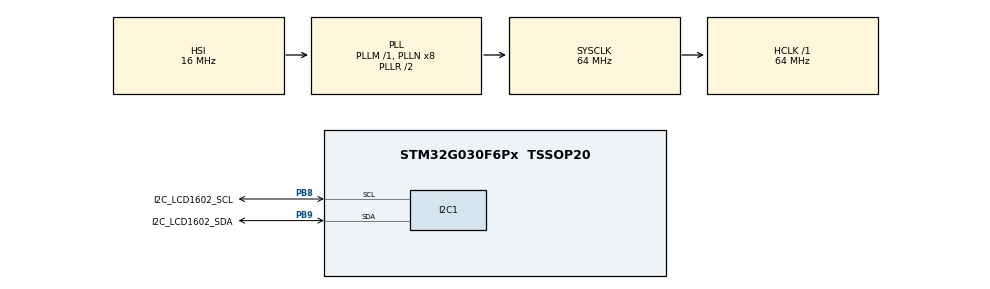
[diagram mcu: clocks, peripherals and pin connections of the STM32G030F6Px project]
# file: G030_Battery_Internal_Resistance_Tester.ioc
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ADC1.Channel-0\#ChannelRegularConversion=ADC_CHANNEL_VREFINT
ADC1.NbrOfConversionFlag=1
ADC1.Rank-0\#ChannelRegularConversion=1
ADC1.SamplingTime-0\#ChannelRegularConversion=ADC_SAMPLINGTIME_COMMON_1
ADC1.SelectedChannel=ADC_CHANNEL_VREFINT
ADC1.master=1
I2C1.Timing=0x10B17DB5
Mcu.Family=STM32G0
Mcu.Name=STM32G030F6Px
Mcu.Package=TSSOP20
PA13.Mode=Serial_Wire
PA13.Signal=SYS_SWDIO
PA14-BOOT0.Mode=Serial_Wire
PA14-BOOT0.Signal=SYS_SWCLK
PA14-BOOT0__PA15.StandardMode=true
PB0__PB1__PB2__PA8.StandardMode=true
PB3__PB4__PB5__PB6.StandardMode=true
PB7__PB8.StandardMode=true
PB8.GPIO_Label=I2C_LCD1602_SCL
PB8.Mode=I2C
PB8.Signal=I2C1_SCL
PB9.GPIO_Label=I2C_LCD1602_SDA
PB9.Mode=I2C
PB9.Signal=I2C1_SDA
PC14-OSC32_IN\ (PC14)__PB9.StandardMode=true
ProjectManager.HeapSize=0x200
ProjectManager.StackSize=0x400
ProjectManager.TargetToolchain=STM32CubeIDE
RCC.ADCFreq_Value=64000000
RCC.AHBFreq_Value=64000000
RCC.CortexFreq_Value=64000000
RCC.EXTERNAL_CLOCK_VALUE=12288000
RCC.HCLKFreq_Value=64000000
RCC.HSE_VALUE=8000000
RCC.HSI_VALUE=16000000
RCC.LSE_VALUE=32768
RCC.SYSCLKFreq_VALUE=64000000
RCC.SYSCLKSource=RCC_SYSCLKSOURCE_PLLCLK
RCC.VCOOutputFreq_Value=128000000
VP_ADC1_Vref_Input.Mode=IN-Vrefint
board=custom

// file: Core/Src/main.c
/* USER CODE BEGIN Header */
/**
  ******************************************************************************
  * @file           : main.c
  * @brief          : Main program body
  ******************************************************************************
  * @attention
  *
  * Copyright (c) 2026 STMicroelectronics.
  * All rights reserved.
  *
  * This software is licensed under terms that can be found in the LICENSE file
  * in the root directory of this software component.
  * If no LICENSE file comes with this software, it is provided AS-IS.
  *
  ******************************************************************************
  */
/* USER CODE END Header */
#include "main.h"

ADC_HandleTypeDef hadc1;

I2C_HandleTypeDef hi2c1;

void SystemClock_Config(void);
static void MX_GPIO_Init(void);
static void MX_ADC1_Init(void);
static void MX_I2C1_Init(void);

/* USER CODE BEGIN 0 */
#define LCD_RS 0x01U
#define LCD_EN 0x04U
#define LCD_BL 0x08U
static uint16_t lcd_address;

static void LCD_Raw(uint8_t b)
{
  (void)HAL_I2C_Master_Transmit(&hi2c1, lcd_address, &b, 1, 100);
}
static void LCD_Nibble(uint8_t n, uint8_t rs)
{
  uint8_t b = (uint8_t)((n & 0xF0U) | LCD_BL | rs);
  LCD_Raw((uint8_t)(b | LCD_EN));
  HAL_Delay(1);
  LCD_Raw(b);
  HAL_Delay(1);
}
static void LCD_Send(uint8_t b, uint8_t rs)
{
  LCD_Nibble(b, rs);
  LCD_Nibble((uint8_t)(b << 4), rs);
}
static void LCD_Cmd(uint8_t c)
{
  LCD_Send(c, 0);
  if (c == 0x01U || c == 0x02U) HAL_Delay(2);
}
static void LCD_Print(const char *p)
{
  while (*p) LCD_Send((uint8_t)*p++, LCD_RS);
}
static uint8_t LCD_Detect(void)
{
  /* Common PCF8574/PCF8574A backpack address range. */
  for (uint8_t a = 0x20U; a <= 0x3FU; a++)
  {
    if (HAL_I2C_IsDeviceReady(&hi2c1, (uint16_t)(a << 1), 2, 20) == HAL_OK)
    {
      lcd_address = (uint16_t)(a << 1);
      return 1;
    }
  }
  return 0;
}
static void LCD_Init(void)
{
  HAL_Delay(50);
  LCD_Raw(LCD_BL);
  HAL_Delay(50);
  LCD_Nibble(0x30, 0);
  HAL_Delay(5);
  LCD_Nibble(0x30, 0);
  HAL_Delay(2);
  LCD_Nibble(0x30, 0);
  LCD_Nibble(0x20, 0);
  LCD_Cmd(0x28);
  LCD_Cmd(0x08);
  LCD_Cmd(0x01);
  LCD_Cmd(0x06);
  LCD_Cmd(0x0C);
}

/* USER CODE END 0 */

int main(void)
{

  /* MCU Configuration--------------------------------------------------------*/

  /* Reset of all peripherals, Initializes the Flash interface and the Systick. */
  HAL_Init();

  /* Configure the system clock */
  SystemClock_Config();

  /* Initialize all configured peripherals */
  MX_GPIO_Init();
  MX_ADC1_Init();
  MX_I2C1_Init();
  /* USER CODE BEGIN 2 */
  if (LCD_Detect())
  {
    LCD_Init();
    LCD_Cmd(0x80);
    LCD_Print("STM32G030 READY");
    LCD_Cmd(0xC0);
    LCD_Print("LCD1602 I2C OK!");
  }

  /* USER CODE END 2 */

  /* Infinite loop */
  while (1)
  {

  }
}

void SystemClock_Config(void)
{
  RCC_OscInitTypeDef RCC_OscInitStruct = {0};
  RCC_ClkInitTypeDef RCC_ClkInitStruct = {0};

  /** Configure the main internal regulator output voltage
  */
  HAL_PWREx_ControlVoltageScaling(PWR_REGULATOR_VOLTAGE_SCALE1);

  /** Initializes the RCC Oscillators according to the specified parameters
  * in the RCC_OscInitTypeDef structure.
  */
  RCC_OscInitStruct.OscillatorType = RCC_OSCILLATORTYPE_HSI;
  RCC_OscInitStruct.HSIState = RCC_HSI_ON;
  RCC_OscInitStruct.HSIDiv = RCC_HSI_DIV1;
  RCC_OscInitStruct.HSICalibrationValue = RCC_HSICALIBRATION_DEFAULT;
  RCC_OscInitStruct.PLL.PLLState = RCC_PLL_ON;
  RCC_OscInitStruct.PLL.PLLSource = RCC_PLLSOURCE_HSI;
  RCC_OscInitStruct.PLL.PLLM = RCC_PLLM_DIV1;
  RCC_OscInitStruct.PLL.PLLN = 8;
  RCC_OscInitStruct.PLL.PLLP = RCC_PLLP_DIV2;
  RCC_OscInitStruct.PLL.PLLR = RCC_PLLR_DIV2;
  if (HAL_RCC_OscConfig(&RCC_OscInitStruct) != HAL_OK)
  {
    Error_Handler();
  }

  /** Initializes the CPU, AHB and APB buses clocks
  */
  RCC_ClkInitStruct.ClockType = RCC_CLOCKTYPE_HCLK|RCC_CLOCKTYPE_SYSCLK
                              |RCC_CLOCKTYPE_PCLK1;
  RCC_ClkInitStruct.SYSCLKSource = RCC_SYSCLKSOURCE_PLLCLK;
  RCC_ClkInitStruct.AHBCLKDivider = RCC_SYSCLK_DIV1;
  RCC_ClkInitStruct.APB1CLKDivider = RCC_HCLK_DIV1;

  if (HAL_RCC_ClockConfig(&RCC_ClkInitStruct, FLASH_LATENCY_2) != HAL_OK)
  {
    Error_Handler();
  }
}

static void MX_ADC1_Init(void)
{

  ADC_ChannelConfTypeDef sConfig = {0};

  /** Configure the global features of the ADC (Clock, Resolution, Data Alignment and number of conversion)
  */
  hadc1.Instance = ADC1;
  hadc1.Init.ClockPrescaler = ADC_CLOCK_SYNC_PCLK_DIV2;
  hadc1.Init.Resolution = ADC_RESOLUTION_12B;
  hadc1.Init.DataAlign = ADC_DATAALIGN_RIGHT;
  hadc1.Init.ScanConvMode = ADC_SCAN_DISABLE;
  hadc1.Init.EOCSelection = ADC_EOC_SINGLE_CONV;
  hadc1.Init.LowPowerAutoWait = DISABLE;
  hadc1.Init.LowPowerAutoPowerOff = DISABLE;
  hadc1.Init.ContinuousConvMode = DISABLE;
  hadc1.Init.NbrOfConversion = 1;
  hadc1.Init.DiscontinuousConvMode = DISABLE;
  hadc1.Init.ExternalTrigConv = ADC_SOFTWARE_START;
  hadc1.Init.ExternalTrigConvEdge = ADC_EXTERNALTRIGCONVEDGE_NONE;
  hadc1.Init.DMAContinuousRequests = DISABLE;
  hadc1.Init.Overrun = ADC_OVR_DATA_PRESERVED;
  hadc1.Init.SamplingTimeCommon1 = ADC_SAMPLETIME_1CYCLE_5;
  hadc1.Init.SamplingTimeCommon2 = ADC_SAMPLETIME_1CYCLE_5;
  hadc1.Init.OversamplingMode = DISABLE;
  hadc1.Init.TriggerFrequencyMode = ADC_TRIGGER_FREQ_HIGH;
  if (HAL_ADC_Init(&hadc1) != HAL_OK)
  {
    Error_Handler();
  }

  /** Configure Regular Channel
  */
  sConfig.Channel = ADC_CHANNEL_VREFINT;
  sConfig.Rank = ADC_REGULAR_RANK_1;
  sConfig.SamplingTime = ADC_SAMPLINGTIME_COMMON_1;
  if (HAL_ADC_ConfigChannel(&hadc1, &sConfig) != HAL_OK)
  {
    Error_Handler();
  }

}

static void MX_I2C1_Init(void)
{

  hi2c1.Instance = I2C1;
  hi2c1.Init.Timing = 0x10B17DB5;
  hi2c1.Init.OwnAddress1 = 0;
  hi2c1.Init.AddressingMode = I2C_ADDRESSINGMODE_7BIT;
  hi2c1.Init.DualAddressMode = I2C_DUALADDRESS_DISABLE;
  hi2c1.Init.OwnAddress2 = 0;
  hi2c1.Init.OwnAddress2Masks = I2C_OA2_NOMASK;
  hi2c1.Init.GeneralCallMode = I2C_GENERALCALL_DISABLE;
  hi2c1.Init.NoStretchMode = I2C_NOSTRETCH_DISABLE;
  if (HAL_I2C_Init(&hi2c1) != HAL_OK)
  {
    Error_Handler();
  }

  /** Configure Analogue filter
  */
  if (HAL_I2CEx_ConfigAnalogFilter(&hi2c1, I2C_ANALOGFILTER_ENABLE) != HAL_OK)
  {
    Error_Handler();
  }

  /** Configure Digital filter
  */
  if (HAL_I2CEx_ConfigDigitalFilter(&hi2c1, 0) != HAL_OK)
  {
    Error_Handler();
  }

}

static void MX_GPIO_Init(void)
{

  /* GPIO Ports Clock Enable */
  __HAL_RCC_GPIOB_CLK_ENABLE();
  __HAL_RCC_GPIOA_CLK_ENABLE();

}

void Error_Handler(void)
{
  __disable_irq();
  while (1)
  {
  }
}
